# CW32L010 register map
Vendor: Wuhan Xinyuan Semiconductor Co.Ltd; Series: ARMCM0P; File version: 1.2
CPU: CM0+ r0p1, little endian, no MPU, no FPU, 3 interrupt priority bits
Registers are 32-bit, read-write, no defined reset value unless marked. A register's access mark holds for its fields unless they carry their own. Offsets are from the block's base; [hi:lo] are bit positions; 'fields as' and 'values as' point back to an identical list.

## I2C1
Base 0x40005800
0x00 BRREN
  [0] EN
0x04 BRR
  [7:0] BRR
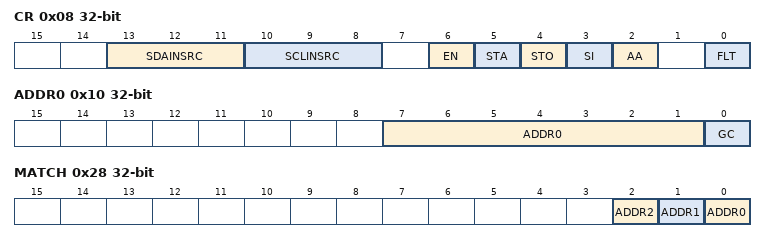
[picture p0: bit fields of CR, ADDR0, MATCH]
0x08 CR — Control register
  [13:11] SDAINSRC, [10:8] SCLINSRC, [6] EN, [5] STA, [4] STO, [3] SI, [2] AA, [0] FLT
0x0C DR — Data register
  [7:0] DR
0x10 ADDR0 — Slave Addrress0
  [7:1] ADDR0, [0] GC
0x14 STAT ro — Status register
  [7:0] STAT
0x20 ADDR1 — Slave Addrress1
  [7:1] ADDR1
0x24 ADDR2 — Slave Addrress2
  [7:1] ADDR2
0x28 MATCH ro — Slave Addrress match flag
  [2] ADDR2, [1] ADDR1, [0] ADDR0

## IRMOD
Base 0x40004080
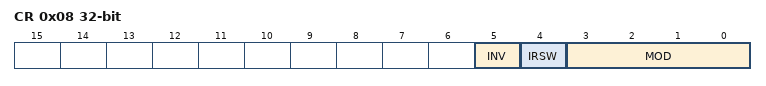
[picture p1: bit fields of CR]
0x08 CR — Input selection register
  [5] INV, [4] IRSW, [3:0] MOD

## IWDT
Base 0x40005000
0x00 KR wo — Key register
  [15:0] KR
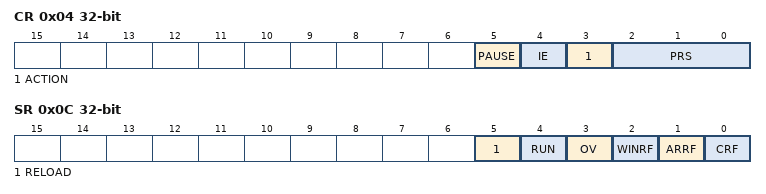
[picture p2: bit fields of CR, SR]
0x04 CR — Control register
  [5] PAUSE, [4] IE, [3] ACTION, [2:0] PRS
0x08 ARR — Auto reload register
  [11:0] ARR
0x0C SR — Status register
  [5] RELOAD ro, [4] RUN ro, [3] OV, [2] WINRF ro, [1] ARRF ro, [0] CRF ro
0x10 WINR — Window register
  [11:0] WINR
0x24 CNT ro — counter
  [11:0] CNT

## LPTIM
Base 0x40006000
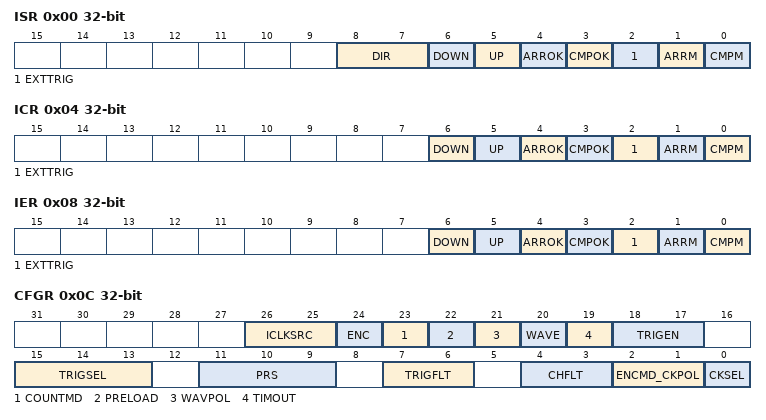
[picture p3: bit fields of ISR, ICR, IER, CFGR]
0x00 ISR ro
  [8:7] DIR, [6] DOWN, [5] UP, [4] ARROK, [3] CMPOK, [2] EXTTRIG, [1] ARRM, [0] CMPM
0x04 ICR
  [6] DOWN, [5] UP, [4] ARROK, [3] CMPOK, [2] EXTTRIG, [1] ARRM, [0] CMPM
0x08 IER
  fields as ICR
0x0C CFGR
  [26:25] ICLKSRC, [24] ENC, [23] COUNTMD, [22] PRELOAD, [21] WAVPOL, [20] WAVE, [19] TIMOUT, [18:17] TRIGEN, [15:13] TRIGSEL, [11:9] PRS, [7:6] TRIGFLT, [4:3] CHFLT, [2:1] ENCMD_CKPOL, [0] CKSEL
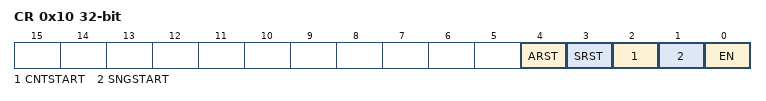
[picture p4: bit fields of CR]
0x10 CR
  [4] ARST, [3] SRST, [2] CNTSTART, [1] SNGSTART, [0] EN
0x14 CMP
  [15:0] CMP
0x18 ARR
  [15:0] ARR
0x1C CNT ro
  [15:0] CNT

## RAM
Base 0x40022400
0x00 IER
  [0] PARITY
0x04 ADDR ro
  [31:0] ADDR rw
0x08 ISR ro
  [0] PARITY
0x0C ICR
  [0] PARITY

## UART1
Base 0x40000C00
Same registers: UART2 0x40001000
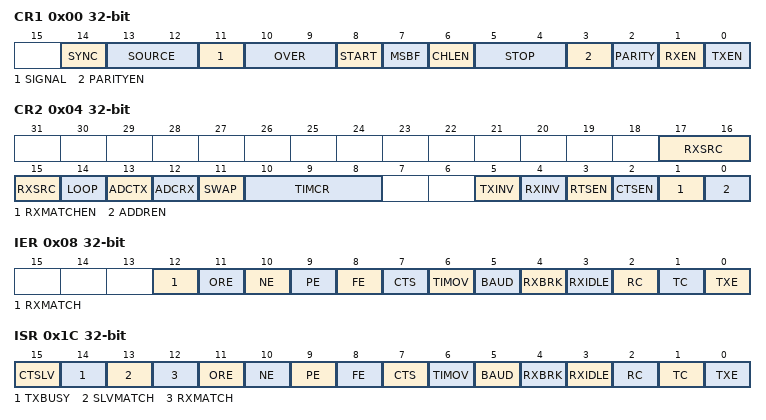
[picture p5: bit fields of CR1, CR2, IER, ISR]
0x00 CR1 — Control register1
  [14] SYNC, [13:12] SOURCE, [11] SIGNAL, [10:9] OVER, [8] START, [7] MSBF, [6] CHLEN, [5:4] STOP, [3] PARITYEN, [2] PARITY, [1] RXEN, [0] TXEN
0x04 CR2 — Control register2
  [17:15] RXSRC, [14] LOOP, [13] ADCTX, [12] ADCRX, [11] SWAP, [10:8] TIMCR, [5] TXINV, [4] RXINV, [3] RTSEN, [2] CTSEN, [1] RXMATCHEN, [0] ADDREN
0x08 IER — Interrupt enable register
  [12] RXMATCH, [11] ORE, [10] NE, [9] PE, [8] FE, [7] CTS, [6] TIMOV, [5] BAUD, [4] RXBRK, [3] RXIDLE, [2] RC, [1] TC, [0] TXE
0x0C BRRI
  [15:0] BRRI
0x10 BRRF
  [3:0] BRRF
0x14 TIMARR
  [23:0] TIMARR
0x18 TIMCNT ro
  [23:0] TIMCNT
0x1C ISR ro — Interrupt status register
  [15] CTSLV, [14] TXBUSY, [13] SLVMATCH, [12] RXMATCH, [11] ORE, [10] NE, [9] PE, [8] FE, [7] CTS, [6] TIMOV, [5] BAUD, [4] RXBRK, [3] RXIDLE, [2] RC, [1] TC, [0] TXE
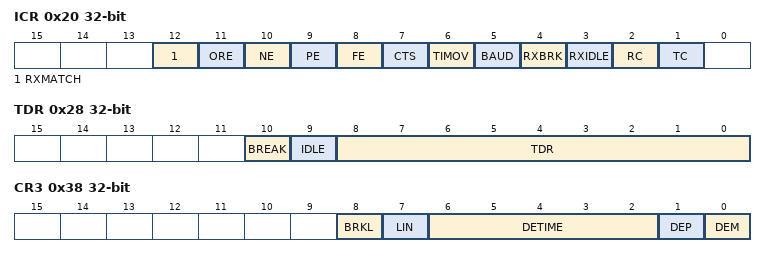
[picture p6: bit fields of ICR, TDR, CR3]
0x20 ICR — Interrupt flag clear register
  [12] RXMATCH, [11] ORE, [10] NE, [9] PE, [8] FE, [7] CTS, [6] TIMOV, [5] BAUD, [4] RXBRK, [3] RXIDLE, [2] RC, [1] TC
0x24 RDR ro — Data reg for read
  [8:0] RDR
0x28 TDR wo — Data reg for write
  [10] BREAK, [9] IDLE, [8:0] TDR
0x30 ADDR — Slave addr
  [7:0] ADDR
0x34 MASK — Slave addr mask
  [7:0] MASK
0x38 CR3 — Control register3
  [8] BRKL, [7] LIN, [6:2] DETIME, [1] DEP, [0] DEM
0x3C RXMATCH
  [8:0] RXMATCH

## LVD
Base 0x400000D0
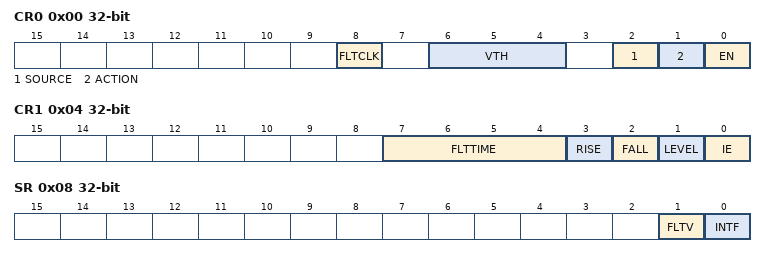
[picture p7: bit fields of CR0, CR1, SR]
0x00 CR0 — Control register0
  [8] FLTCLK, [6:4] VTH, [2] SOURCE, [1] ACTION, [0] EN
0x04 CR1 — Control register1
  [7:4] FLTTIME, [3] RISE, [2] FALL, [1] LEVEL, [0] IE
0x08 SR — status register
  [1] FLTV ro, [0] INTF

## RTC
Base 0x40004400
0x00 KEY wo
  [7:0] KEY
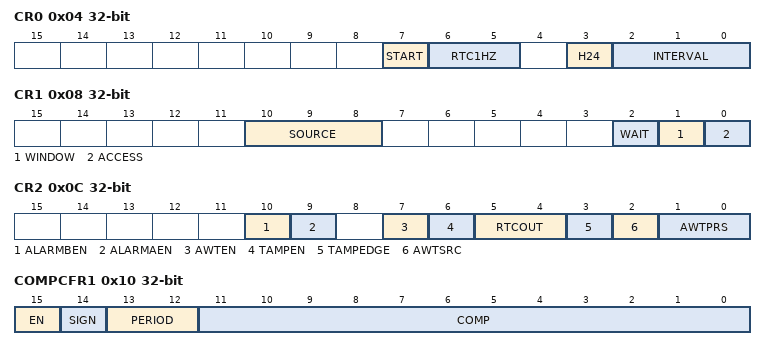
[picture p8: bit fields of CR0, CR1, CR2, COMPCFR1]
0x04 CR0
  [7] START, [6:5] RTC1HZ, [3] H24, [2:0] INTERVAL
0x08 CR1
  [10:8] SOURCE, [2] WAIT ro, [1] WINDOW ro, [0] ACCESS
0x0C CR2
  [10] ALARMBEN, [9] ALARMAEN, [7] AWTEN, [6] TAMPEN, [5:4] RTCOUT, [3] TAMPEDGE, [2] AWTSRC, [1:0] AWTPRS
0x10 COMPCFR1
  [15] EN, [14] SIGN, [13:12] PERIOD, [11:0] COMP
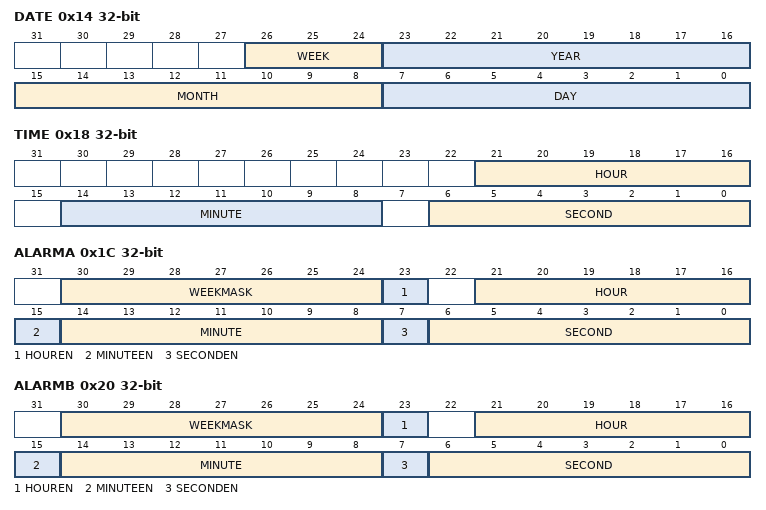
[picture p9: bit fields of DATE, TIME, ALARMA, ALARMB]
0x14 DATE
  [26:24] WEEK, [23:16] YEAR, [15:8] MONTH, [7:0] DAY
0x18 TIME
  [21:16] HOUR, [14:8] MINUTE, [6:0] SECOND
0x1C ALARMA
  [30:24] WEEKMASK, [23] HOUREN, [21:16] HOUR, [15] MINUTEEN, [14:8] MINUTE, [7] SECONDEN, [6:0] SECOND
0x20 ALARMB
  fields as ALARMA
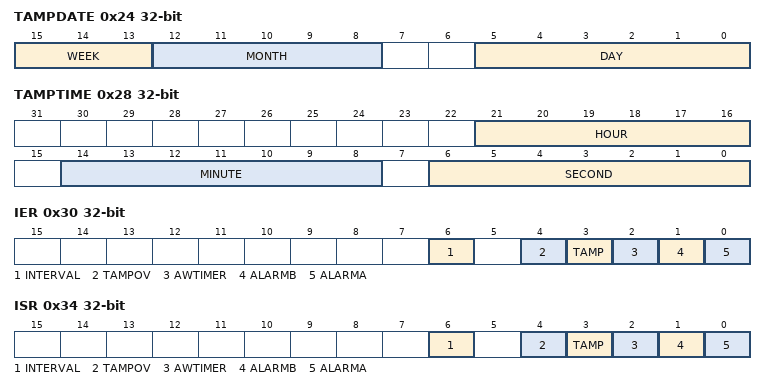
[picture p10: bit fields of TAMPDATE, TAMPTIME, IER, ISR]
0x24 TAMPDATE ro
  [15:13] WEEK, [12:8] MONTH, [5:0] DAY
0x28 TAMPTIME ro
  [21:16] HOUR, [14:8] MINUTE, [6:0] SECOND
0x2C AWTARR
  [15:0] ARR
0x30 IER
  [6] INTERVAL, [4] TAMPOV, [3] TAMP, [2] AWTIMER, [1] ALARMB, [0] ALARMA
0x34 ISR ro
  fields as IER
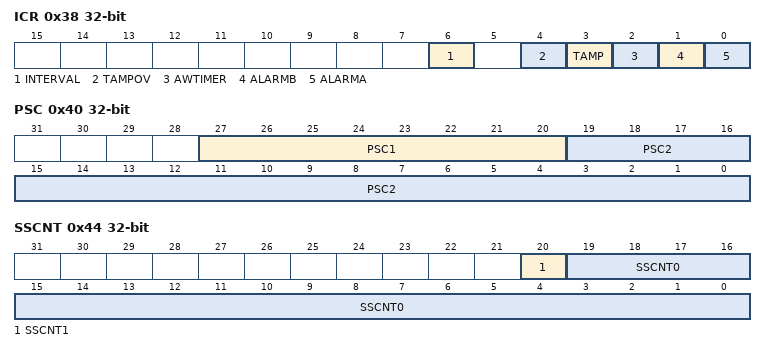
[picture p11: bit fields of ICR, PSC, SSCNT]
0x38 ICR
  fields as IER
0x3C AWTCNT ro
  [15:0] CNT
0x40 PSC
  [27:20] PSC1, [19:0] PSC2
0x44 SSCNT ro
  [20] SSCNT1, [19:0] SSCNT0
0x54 COMPCFR2
  [10:0] PCLKCNT
0x58 COMPCFR3 ro
  [10:0] PCLKCNT
